# C2C register map
Vendor: Texas Instruments
Peripheral module from a debugger description file (folder omap4430).
Registers are 32-bit, access per field, reset values left out (the file's numbers can be read two ways) unless marked. A register's access mark holds for its fields unless they carry their own. Offsets are as the file gives them; lines under a group give offsets from that group; [hi:lo] are bit positions; {n}, {i} and the like mark numbered series; 'fields as' and 'values as' point back to an identical list; <NAME> marks a mode.

## C2C
0x00 C2C_REVISION ro — IP Revision identifier (X.Y.R) Used by software to track features, bugs, and compatibility
  [31:0] REVISION — IP Revision
0x04 C2C_SYSCONFIG ro — System configuration register (not used)
0x08 C2C_SYSSTATUS ro — Reserved
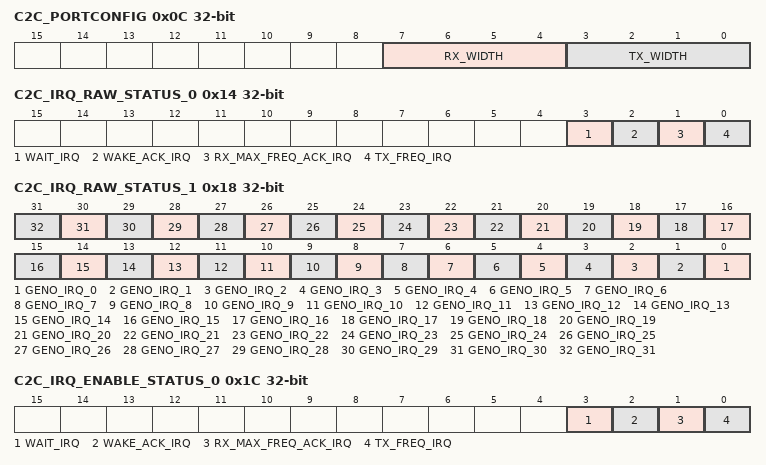
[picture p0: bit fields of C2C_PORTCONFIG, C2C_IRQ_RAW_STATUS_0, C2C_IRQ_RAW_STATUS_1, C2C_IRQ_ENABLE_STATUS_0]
0x0C C2C_PORTCONFIG — This register defines the widths of the TX and RX buses on the C2C interface.
  [7:4] RX_WIDTH rw — 0000: Bus width is set to 8 bits (default mode).Other values are reserved, and should not be used. .
    1=Bus width is set to 10 bits (possible only if TX = 8); 10=Bus width is set to 16 bits
  [3:0] TX_WIDTH rw — 0000: Bus width is set to 8 bits.Other values are reserved, and shall not be used. .
    1=Bus width is set to 10 bits (possible only if RX = 8); 10=Bus width is set to 16 bits (default mode)
0x10 C2C_MIRRORMODE — This register sets the C2C L3 in mirror mode. See debug section.
  [0] MIRRORMODE rw
    0=Functional default mode; 1=Mirror mode for debug
0x14 C2C_IRQ_RAW_STATUS_0 access not given — Interrupt status register (OCP-compliant IRQ line) for C2c_Sscm_Irq(0), regardless of enable settings
  [3] WAIT_IRQ — Reading 1 indicates WAIT value in WAIT register has been modified by distant C2C.Writing 1 to this bit sets the bit. . Writing 0 has no effect. . (access RW W1toSet)
  [2] WAKE_ACK_IRQ — Reading 1 indicates WAKE_ACK value in the WAKE_ACK register has been modified by distant C2C.Writing 1 to this bit sets the bit. . Writing 0 has no effect. . (access RW W1toSet)
  [1] RX_MAX_FREQ_ACK_IRQ — Reading 1 indicates GPI is not turned on OR RX_MAX_FREQ_ACK value in the RX_MAX_FREQ_ACK register equal RX_MAX_FREQ value in the RX_MAX_FREQ register.Writing 1 to this bit sets the bit. . Writing 0 has no effect. . (access RW W1toSet)
  [0] TX_FREQ_IRQ — Reading 1 indicates that the FCLK_FREQ value in the FCLK_FREQ register has been updated AND the SSCM has finished updating the new division for the TX clock.Writing 1 to this bit sets the bit. . Writing 0 has no effect. . (access RW W1toSet)
0x18 C2C_IRQ_RAW_STATUS_1 access not given
  [n] GENO_IRQ_{n} (n=0..31) — Reading 1 indicates C2c_Sscm_GENO ({n}) signal and GENO_{n} value in GENO_STATUS register have been modified by distant C2C.Writing 1 to this bit sets the bit. . Writing 0 has no effect. . (access RW W1toSet)
0x1C C2C_IRQ_ENABLE_STATUS_0 access not given
  [3] WAIT_IRQ — Reading 1 indicates WAIT value in WAIT register has been modified by distant C2C and interrupt source is not masked. Writing 1 to this bit clears the bit. Writing 0 has no effect. (access RW W1toClr)
  [2] WAKE_ACK_IRQ — Reading 1 indicates WAKE_ACK value in the WAKE_ACK register has been modified by distant C2C and interrupt source is not masked. Writing 1 to this bit clears the bit. Writing 0 has no effect. (access RW W1toClr)
  [1] RX_MAX_FREQ_ACK_IRQ — Reading 1 indicates GPI is not turned on OR RX_MAX_FREQ_ACK value in the RX_MAX_FREQ_ACK register equal RX_MAX_FREQ value in the RX_MAX_FREQ register. (access RW W1toClr)
  [0] TX_FREQ_IRQ — Reading 1 indicates that the FCLK_FREQ value in the FCLK_FREQ register has been updated AND the SSCM has finished updating the new division for the Tx clock. (access RW W1toClr)
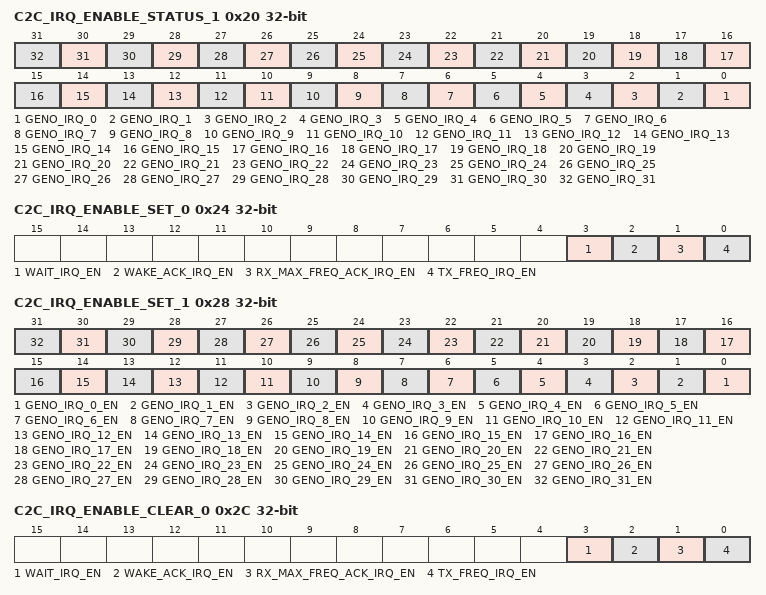
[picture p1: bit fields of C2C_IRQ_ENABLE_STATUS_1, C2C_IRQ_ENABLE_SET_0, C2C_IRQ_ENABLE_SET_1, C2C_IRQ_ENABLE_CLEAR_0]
0x20 C2C_IRQ_ENABLE_STATUS_1 access not given
  [n] GENO_IRQ_{n} (n=0..31) — Reading 1 indicates C2c_Sscm_GENO ({n}) signal and GENO_{n} value in GENO_STATUS register have been modified by distant C2C and interrupt source is not masked. Writing 1 to this bit clears the bit. Writing 0 has no effect. (access RW W1toClr)
0x24 C2C_IRQ_ENABLE_SET_0 access not given
  [3] WAIT_IRQ_EN — Interrupt enable for WAIT IRQ. Writing 1 to this bit sets the bit. Writing 0 has no effect. (access RW W1toSet)
  [2] WAKE_ACK_IRQ_EN — Interrupt enable for WAKE_ACK IRQ. Writing 1 to this bit sets the bit. Writing 0 has no effect. (access RW W1toSet)
  [1] RX_MAX_FREQ_ACK_IRQ_EN — Interrupt enable for RX_MAX_FREQ_ACK IRQ. Writing 1 to this bit sets the bit. Writing 0 has no effect. (access RW W1toSet)
  [0] TX_FREQ_IRQ_EN — Interrupt enable for TX_FREQ IRQ. Writing 1 to this bit sets the bit. Writing 0 has no effect. (access RW W1toSet)
0x28 C2C_IRQ_ENABLE_SET_1 access not given
  [n] GENO_IRQ_{n}_EN (n=0..31) — Interrupt enable for GENO_IRQ_{n} IRQ. (access RW W1toSet)
0x2C C2C_IRQ_ENABLE_CLEAR_0 access not given
  [3] WAIT_IRQ_EN — Interrupt enable for WAIT IRQ. (access RW W1toClr)
  [2] WAKE_ACK_IRQ_EN — Interrupt enable for WAKE_ACK IRQ. (access RW W1toClr)
  [1] RX_MAX_FREQ_ACK_IRQ_EN — Interrupt enable for RX_MAX_FREQ_ACK IRQ. (access RW W1toClr)
  [0] TX_FREQ_IRQ_EN — Interrupt enable for TX_FREQ IRQ. (access RW W1toClr)
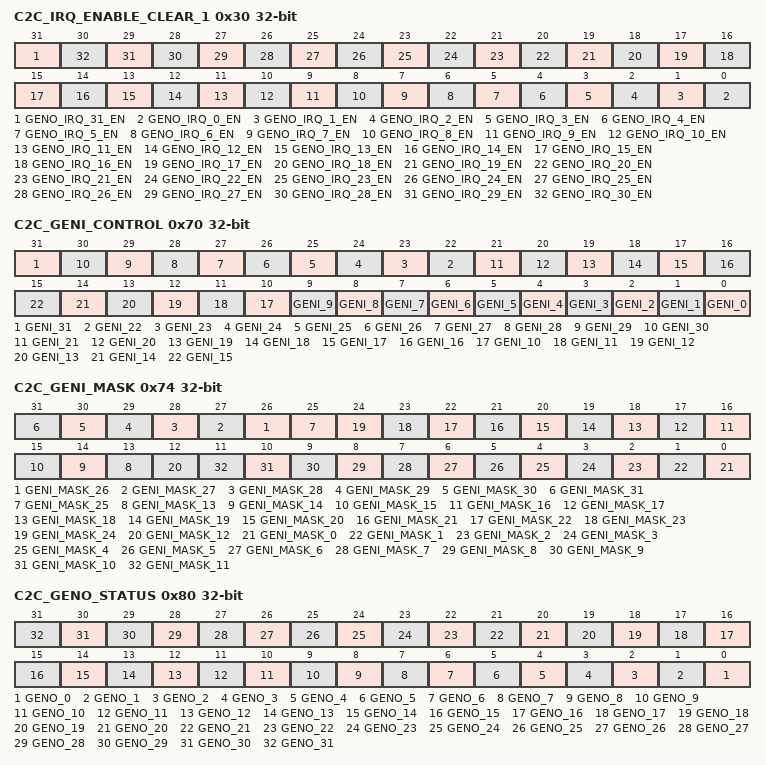
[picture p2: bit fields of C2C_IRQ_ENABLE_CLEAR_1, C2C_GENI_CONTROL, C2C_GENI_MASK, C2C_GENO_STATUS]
0x30 C2C_IRQ_ENABLE_CLEAR_1 access not given
  [31] GENO_IRQ_31_EN — Interrupt enable for GENO_IRQ_31 IRQ. Writing 1 to this bit clears the bit. Writing 0 has no effect. (access RW W1toClr)
  [n] GENO_IRQ_{n}_EN (n=0..30) — Interrupt enable for GENO_IRQ_{n} IRQ. (access RW W1toClr)
0x40 C2C_FCLK_FREQ
  [9:0] FCLK_FREQ rw — Value of the Functional clock frequency according to OPP written by software. Default value is 400 (MHz).
0x44 C2C_RX_MAX_FREQ
  [9:0] RX_MAX_FREQ rw — Value of the requested RX maximum clock frequency according to OPP written by software. Default value is 50 (MHz).
0x48 C2C_TX_MAX_FREQ
  [9:0] TX_MAX_FREQ rw — Value of the requested TX maximum clock frequency set by distant C2C. Default value is 50 (MHz).
0x4C C2C_RX_MAX_FREQ_ACK
  [9:0] RX_MAX_FREQ_ACK rw — Acknowledged maximum Rx clock frequency. Set by distant C2C. Default value is 50 (MHz).
0x50 C2C_WAKE_REQ
  [0] WAKE_REQ rw — Value of the WAKE_REQ set by software
0x54 C2C_WAKE_ACK
  [0] WAKE_ACK rw — Value of the WAKE_ACK set by distant C2C
0x60 C2C_STANDBY
  [0] STANDBY rw — Value of the STANDBY set by software
0x64 C2C_STANDBY_IN
  [0] STANDBY rw — Value of the STANDBY set by distant C2C
0x68 C2C_WAIT
  [0] WAIT rw — Value of the WAIT set by distant C2C
0x70 C2C_GENI_CONTROL rw
  [31] GENI_31 — If GENI_MASK_31 in GENI_MASK register is reset, GENI_31 is the value of C2C_Sscm_GenI_31 and cannot be modified by software. (signal is not masked)If GENI_MASK_31 is set (signal is masked), GENI_31 can be modified by software.
  [n] GENI_{n} (n=22..30) — f GENI_MASK_{n} in GENI_MASK register is reset, GENI_{n} is the value of C2C_Sscm_GenI_{n} and cannot be modified by software. (signal is not masked)If GENI_MASK_{n} is set (signal is masked), GENI_{n} can be modified by software.
  [21] GENI_21 — f GENI_MASK_21 in GENI_MASK register is reset, GENI_21 is the value of C2C_Sscm_GenI_31 and cannot be modified by software. (signal is not masked)If GENI_MASK_21 is set (signal is masked), GENI_21 can be modified by software.
  [20] GENI_20 — f GENI_MASK_20 in GENI_MASK register is reset, GENI_20 is the value of C2C_Sscm_GenI_20 and cannot be modified by software. (signal is not masked)If GENI_MASK_20 is set (signal is masked), GENI_20 can be modified by software.
  [19] GENI_19 — f GENI_MASK_19 in GENI_MASK register is reset, GENI_19 is the value of C2C_Sscm_GenI_19 and cannot be modified by software. (signal is not masked)If GENI_MASK_19 is set (signal is masked), GENI_19 can be modified by software.
  [18] GENI_18 — f GENI_MASK_18 in GENI_MASK register is reset, GENI_18 is the value of C2C_Sscm_GenI_31 and cannot be modified by software. (signal is not masked)If GENI_MASK_18 is set (signal is masked), GENI_18 can be modified by software.
  [17] GENI_17 — f GENI_MASK_17 in GENI_MASK register is reset, GENI_17 is the value of C2C_Sscm_GenI_31 and cannot be modified by software. (signal is not masked)If GENI_MASK_17 is set (signal is masked), GENI_17 can be modified by software.
  [16] GENI_16 — f GENI_MASK_16 in GENI_MASK register is reset, GENI_16 is the value of C2C_Sscm_GenI_16 and cannot be modified by software. (signal is not masked)If GENI_MASK_156is set (signal is masked), GENI_16 can be modified by software.
  [n] GENI_{n} (n=0..15) — f GENI_MASK_{n} in GENI_MASK register is reset, GENI_{n} is the value of C2C_Sscm_GenI_{n} and cannot be modified by software. (signal is not masked)If GENI_MASK_{n} is set (signal is masked), GENI_{n} can be modified by software.
0x74 C2C_GENI_MASK rw
  [n] GENI_MASK_{n} (n=26..31) — If GENI_MASK_{n} is reset, C2C_Sscm_GenI_{n} signal is not masked If GENI_MASK_{n} is set, signal is masked.
  [25] GENI_MASK_25 — If GENI_MASK_26 is reset, C2C_Sscm_GenI_25 signal is not masked If GENI_MASK_26 is set, signal is masked.
  [n] GENI_MASK_{n} (n=13..24) — If GENI_MASK_{n} is reset, C2C_Sscm_GenI_{n} signal is not masked If GENI_MASK_{n} is set, signal is masked.
  [12] GENI_MASK_12 — If GENI_MASK_12is reset, C2C_Sscm_GenI_12 signal is not masked If GENI_MASK_12 is set, signal is masked.
  [n] GENI_MASK_{n} (n=0..11) — If GENI_MASK_{n} is reset, C2C_Sscm_GenI_{n} signal is not masked If GENI_MASK_{n} is set, signal is masked.
0x80 C2C_GENO_STATUS rw
  [n] GENO_{n} (n=0..31) — GENO_{n} is the value of C2C_Sscm_GenO_{n} signal.
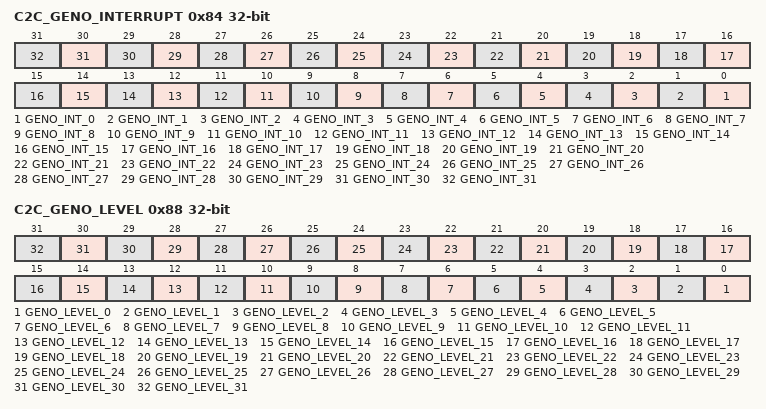
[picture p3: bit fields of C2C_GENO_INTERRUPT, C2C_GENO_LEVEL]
0x84 C2C_GENO_INTERRUPT rw
  [n] GENO_INT_{n} (n=0..31) — If GENO_INT_{n}=0, GENO_IRQ_{n}=1 when GENO_{n} toggles; If GENO_INT_{n}=1: IF GENO_LEVEL_{n}=0, GENO_IRQ_{n} =1 when GENO_{n} toggles to 0. IF GENO_LEVEL_{n}=1, GENO_IRQ_{n} =1 when GENO_{n} toggles to 1.
0x88 C2C_GENO_LEVEL rw
  [n] GENO_LEVEL_{n} (n=0..31) — IF GENO_LEVEL_{n}=0, GENO_IRQ_{n} =1 when GENO_{n} toggles to 0. IF GENO_LEVEL_{n}=1, GENO_IRQ_{n} =1 when GENO_{n} toggles to 1.
